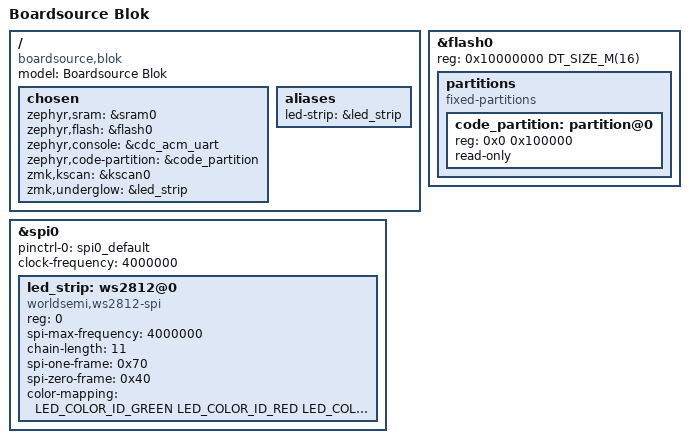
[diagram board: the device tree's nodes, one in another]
/dts-v1/;

#include <rpi_pico/rp2040.dtsi>
#include <dt-bindings/led/led.h>

/ {
    model = "Boardsource Blok";
    compatible = "boardsource,blok";

    chosen {
        zephyr,sram = &sram0;
        zephyr,flash = &flash0;
        zephyr,console = &cdc_acm_uart;
        zephyr,code-partition = &code_partition;
        zmk,kscan = &kscan0;
        zmk,underglow = &led_strip;
    };

    aliases {
        led-strip = &led_strip;
    };
};

&spi0 {
    status = "okay";
    pinctrl-0 = <&spi0_default>;
    pinctrl-names = "default";
    clock-frequency = <4000000>;

    led_strip: ws2812@0 {
        compatible = "worldsemi,ws2812-spi";
        reg = <0>;
        spi-max-frequency = <4000000>;
        chain-length = <11>;
        spi-one-frame = <0x70>;
        spi-zero-frame = <0x40>;
        color-mapping = <LED_COLOR_ID_GREEN LED_COLOR_ID_RED LED_COLOR_ID_BLUE>;
        status = "okay";
    };
};

&flash0 {
    status = "okay";
    reg = <0x10000000 DT_SIZE_M(16)>;

    partitions {
        compatible = "fixed-partitions";
        #address-cells = <1>;
        #size-cells = <1>;

        code_partition: partition@0 {
            reg = <0x0 0x100000>;
            read-only;
        };
    };
};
